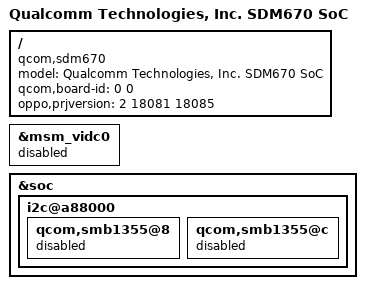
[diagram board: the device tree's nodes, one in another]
/* Copyright (c) 2017, The Linux Foundation. All rights reserved.
 *
 * This program is free software; you can redistribute it and/or modify
 * it under the terms of the GNU General Public License version 2 and
 * only version 2 as published by the Free Software Foundation.
 *
 * This program is distributed in the hope that it will be useful,
 * but WITHOUT ANY WARRANTY; without even the implied warranty of
 * MERCHANTABILITY or FITNESS FOR A PARTICULAR PURPOSE.  See the
 * GNU General Public License for more details.
 */

/dts-v1/;

#include "sdm670.dtsi"

/ {
	model = "Qualcomm Technologies, Inc. SDM670 SoC";
	compatible = "qcom,sdm670";
	qcom,board-id = <0 0>;
	oppo,prjversion = <2 18081 18085>;
};

/* efuse SKU_VERSION_1 为单核 SKU: vidc0(sku-index=0) probe 必失败, 编解码由 vidc1 全覆盖 */
&msm_vidc0 {
	status = "disabled";
};

/* PBEM00 未贴装 SMB1355 并充芯片: 基座预置 disabled 桩(同 nx30p6093 先例), 原厂 dtbo
   注入同名节点不带 status 属性, 合并后保持禁用, 消除 i2c0 0x08/0x0C 地址 NACK */
&soc {
	i2c@a88000 {
		qcom,smb1355@8 {
			status = "disabled";
		};
		qcom,smb1355@c {
			status = "disabled";
		};
	};
};
